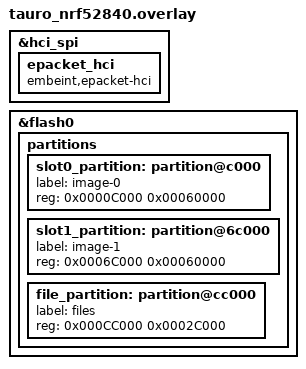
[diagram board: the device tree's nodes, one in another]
/* ePacket HCI support */
&hci_spi {
	epacket_hci: epacket_hci {
		compatible = "embeint,epacket-hci";
	};
};

/* Allocate space for patch files */
/delete-node/ &slot0_partition;
/delete-node/ &slot1_partition;

&flash0 {
	partitions {
		slot0_partition: partition@c000 {
			label = "image-0";
			reg = <0x0000C000 0x00060000>;
		};
		slot1_partition: partition@6c000 {
			label = "image-1";
			reg = <0x0006C000 0x00060000>;
		};
		file_partition: partition@cc000 {
			label = "files";
			reg = <0x000CC000 0x0002C000>;
		};
	};
};
